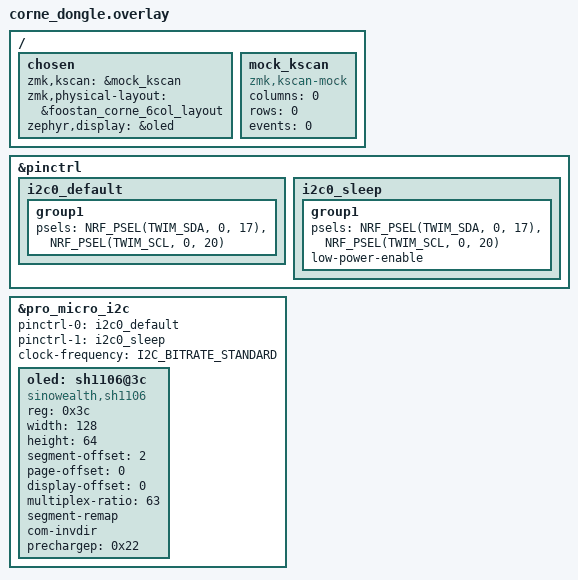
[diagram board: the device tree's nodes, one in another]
/*
 * Copyright (c) 2026 The ZMK Contributors
 * SPDX-License-Identifier: MIT
 */

#include "corne-layouts.dtsi"

/ {
    chosen {
        zmk,kscan = &mock_kscan;
        zmk,physical-layout = &foostan_corne_6col_layout;
        zephyr,display = &oled;
    };

    mock_kscan: mock_kscan {
        compatible = "zmk,kscan-mock";
        columns = <0>;
        rows = <0>;
        events = <0>;
    };
};

&pinctrl {
    i2c0_default: i2c0_default {
        group1 {
            psels = <NRF_PSEL(TWIM_SDA, 0, 17)>,
                    <NRF_PSEL(TWIM_SCL, 0, 20)>;
        };
    };

    i2c0_sleep: i2c0_sleep {
        group1 {
            psels = <NRF_PSEL(TWIM_SDA, 0, 17)>,
                    <NRF_PSEL(TWIM_SCL, 0, 20)>;
            low-power-enable;
        };
    };
};

&pro_micro_i2c {
    status = "okay";
    pinctrl-0 = <&i2c0_default>;
    pinctrl-1 = <&i2c0_sleep>;
    pinctrl-names = "default", "sleep";
    clock-frequency = <I2C_BITRATE_STANDARD>;

    oled: sh1106@3c {
        compatible = "sinowealth,sh1106";
        reg = <0x3c>;
        width = <128>;
        height = <64>;
        segment-offset = <2>;
        page-offset = <0>;
        display-offset = <0>;
        multiplex-ratio = <63>;
        segment-remap;
        com-invdir;
        prechargep = <0x22>;
    };
};
